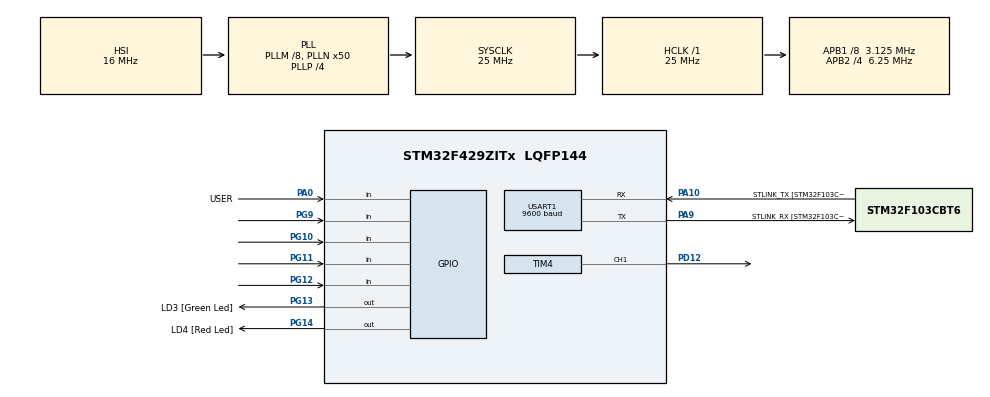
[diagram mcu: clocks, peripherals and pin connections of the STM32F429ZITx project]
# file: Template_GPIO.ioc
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Mcu.Family=STM32F4
Mcu.Name=STM32F429ZITx
Mcu.Package=LQFP144
NVIC.PriorityGroup=NVIC_PRIORITYGROUP_4
NVIC.USART1_IRQn=true\:0\:0\:false\:false\:true\:true\:true\:true
PA0/WKUP.GPIO_Label=USER
PA0/WKUP.Signal=GPIO_Input
PA10.GPIO_Label=STLINK_TX [STM32F103CBT6_PA2]
PA10.Mode=Asynchronous
PA10.Signal=USART1_RX
PA13.GPIO_Label=SWDIO
PA13.Mode=Serial_Wire
PA13.Signal=SYS_JTMS-SWDIO
PA14.GPIO_Label=SWCLK
PA14.Mode=Serial_Wire
PA14.Signal=SYS_JTCK-SWCLK
PA9.GPIO_Label=STLINK_RX [STM32F103CBT6_PA3]
PA9.Mode=Asynchronous
PA9.Signal=USART1_TX
PD12.Signal=S_TIM4_CH1
PG10.Signal=GPIO_Input
PG11.Signal=GPIO_Input
PG12.Signal=GPIO_Input
PG13.GPIO_Label=LD3 [Green Led]
PG13.Signal=GPIO_Output
PG14.GPIO_Label=LD4 [Red Led]
PG14.GPIO_Mode=GPIO_MODE_OUTPUT_PP
PG14.GPIO_PuPd=GPIO_NOPULL
PG14.GPIO_Speed=GPIO_SPEED_FREQ_LOW
PG14.Signal=GPIO_Output
PG9.Signal=GPIO_Input
PH0/OSC_IN.GPIO_Label=PH0-OSC_IN
PH0/OSC_IN.Mode=HSE-External-Oscillator
PH0/OSC_IN.Signal=RCC_OSC_IN
PH1/OSC_OUT.GPIO_Label=PH1-OSC_OUT
PH1/OSC_OUT.Mode=HSE-External-Oscillator
PH1/OSC_OUT.Signal=RCC_OSC_OUT
ProjectManager.HeapSize=0x200
ProjectManager.StackSize=0x400
ProjectManager.TargetToolchain=MDK-ARM V5.32
RCC.48MHZClocksFreq_Value=14285714.285714285
RCC.AHBFreq_Value=25000000
RCC.APB1CLKDivider=RCC_HCLK_DIV8
RCC.APB1Freq_Value=3125000
RCC.APB1TimFreq_Value=6250000
RCC.APB2CLKDivider=RCC_HCLK_DIV4
RCC.APB2Freq_Value=6250000
RCC.APB2TimFreq_Value=12500000
RCC.CortexFreq_Value=25000000
RCC.HCLKFreq_Value=25000000
RCC.HSE_VALUE=8000000
RCC.HSI_VALUE=16000000
RCC.LSE_VALUE=32768
RCC.PLLM=8
RCC.PLLN=50
RCC.PLLP=RCC_PLLP_DIV4
RCC.PLLQ=7
RCC.SYSCLKFreq_VALUE=25000000
RCC.SYSCLKSource=RCC_SYSCLKSOURCE_PLLCLK
RCC.VCOOutputFreq_Value=100000000
SH.S_TIM4_CH1.0=TIM4_CH1,PWM Generation1 CH1
TIM4.Channel-PWM\ Generation1\ CH1=TIM_CHANNEL_1
TIM4.OCMode_PWM-PWM\ Generation1\ CH1=TIM_OCMODE_PWM2
TIM4.OCPolarity_1=TIM_OCPOLARITY_LOW
TIM4.Period=8399
USART1.BaudRate=9600
USART1.VirtualMode=VM_ASYNC
VP_TIM4_VS_ClockSourceINT.Mode=Internal
board=STM32F429I-DISC1

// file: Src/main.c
/* USER CODE BEGIN Header */
/**
  ******************************************************************************
  * @file           : main.c
  * @brief          : Proiect MC - Control Ventilator cu Joystick si PWM
  ******************************************************************************
  */
/* USER CODE END Header */

#include "main.h"
#include <stdio.h>

TIM_HandleTypeDef htim4;
UART_HandleTypeDef huart1;

/* USER CODE BEGIN PV */
float pwm_value = 0.0f;
// Variabile pentru a afisa mesajele o singura data la apasare
uint8_t lock_A = 0, lock_B = 0, lock_C = 0, lock_D = 0;
/* USER CODE END PV */

void SystemClock_Config(void);
static void MX_GPIO_Init(void);
static void MX_USART1_UART_Init(void);
static void MX_TIM4_Init(void);

/* USER CODE BEGIN 0 */
// Redirectionare printf catre UART
#ifdef __GNUC__
  #define PUTCHAR_PROTOTYPE int __io_putchar(int ch)
#else
  #define PUTCHAR_PROTOTYPE int fputc(int ch, FILE *f)
#endif

PUTCHAR_PROTOTYPE
{
  HAL_UART_Transmit(&huart1, (uint8_t *)&ch, 1, 0xFFFF);
  return ch;
}
/* USER CODE END 0 */

int main(void)
{
  /* MCU Configuration */
  HAL_Init();
  SystemClock_Config();

  /* Initialize all configured peripherals */
  MX_GPIO_Init();
  MX_USART1_UART_Init();
  MX_TIM4_Init();

  /* USER CODE BEGIN 2 */
  // Pornire PWM pe pinul PD12
  HAL_TIM_PWM_Start(&htim4, TIM_CHANNEL_1);

  HAL_Delay(500);
  printf("\n\r====================================\r\n");
  printf("   PROIECT MC - CONTROL VENTILATOR\r\n");
  printf("   Studenti: Baroiu Vladut-Andrei, Epure Alexandru-Valentin\r\n");
  printf("   Grupa: 3132A\r\n");
  printf("====================================\r\n\r\n");
  /* USER CODE END 2 */

  while (1)
  {
    /* 1. JOY A (PG6) -> OPRIT */
    if (HAL_GPIO_ReadPin(GPIOG, GPIO_PIN_6) == GPIO_PIN_RESET) {
      if (lock_A == 0) {
        pwm_value = 0.0f;
        __HAL_TIM_SET_COMPARE(&htim4, TIM_CHANNEL_1, 0);
        printf("Comanda: OPRIT (0%%)\r\n");
        lock_A = 1;
      }
    } else { lock_A = 0; }

    /* 2. JOY B (PG9) -> MAXIM */
    if (HAL_GPIO_ReadPin(GPIOG, GPIO_PIN_9) == GPIO_PIN_RESET) {
      if (lock_B == 0) {
        pwm_value = 1.0f;
        __HAL_TIM_SET_COMPARE(&htim4, TIM_CHANNEL_1, 8399);
        printf("Comanda: MAXIM (100%%)\r\n");
        lock_B = 1;
      }
    } else { lock_B = 0; }

    /* 3. JOY C (PG10) -> CRESTE VITEZA +10% */
    if (HAL_GPIO_ReadPin(GPIOG, GPIO_PIN_10) == GPIO_PIN_RESET) {
      if (lock_C == 0) {
        if(pwm_value < 1.0f) pwm_value += 0.1f;
        if(pwm_value > 1.0f) pwm_value = 1.0f;
        __HAL_TIM_SET_COMPARE(&htim4, TIM_CHANNEL_1, (uint32_t)(pwm_value * 8399));
        printf("Turatie: %d%%\r\n", (int)(pwm_value * 100 + 0.5f));
        lock_C = 1;
      }
    } else { lock_C = 0; }

    /* 4. JOY D (PG11) -> SCADE VITEZA -10% */
    if (HAL_GPIO_ReadPin(GPIOG, GPIO_PIN_11) == GPIO_PIN_RESET) {
      if (lock_D == 0) {
        if(pwm_value > 0.0f) pwm_value -= 0.1f;
        if(pwm_value < 0.0f) pwm_value = 0.0f;
        __HAL_TIM_SET_COMPARE(&htim4, TIM_CHANNEL_1, (uint32_t)(pwm_value * 8399));
        printf("Turatie: %d%%\r\n", (int)(pwm_value * 100 + 0.5f));
        lock_D = 1;
      }
    } else { lock_D = 0; }

    // Feedback vizual
    if (pwm_value > 0.01f) {
        HAL_GPIO_WritePin(GPIOG, GPIO_PIN_13, GPIO_PIN_SET);
        HAL_GPIO_WritePin(GPIOG, GPIO_PIN_14, GPIO_PIN_RESET);
    } else {
        HAL_GPIO_WritePin(GPIOG, GPIO_PIN_13, GPIO_PIN_RESET);
        HAL_GPIO_WritePin(GPIOG, GPIO_PIN_14, GPIO_PIN_SET);
    }

    HAL_Delay(20);
  }
}

void SystemClock_Config(void)
{
  RCC_OscInitTypeDef RCC_OscInitStruct = {0};
  RCC_ClkInitTypeDef RCC_ClkInitStruct = {0};

  __HAL_RCC_PWR_CLK_ENABLE();
  __HAL_PWR_VOLTAGESCALING_CONFIG(PWR_REGULATOR_VOLTAGE_SCALE3);

  RCC_OscInitStruct.OscillatorType = RCC_OSCILLATORTYPE_HSI;
  RCC_OscInitStruct.HSIState = RCC_HSI_ON;
  RCC_OscInitStruct.HSICalibrationValue = RCC_HSICALIBRATION_DEFAULT;
  RCC_OscInitStruct.PLL.PLLState = RCC_PLL_ON;
  RCC_OscInitStruct.PLL.PLLSource = RCC_PLLSOURCE_HSI;
  RCC_OscInitStruct.PLL.PLLM = 8;
  RCC_OscInitStruct.PLL.PLLN = 50;
  RCC_OscInitStruct.PLL.PLLP = RCC_PLLP_DIV4;
  RCC_OscInitStruct.PLL.PLLQ = 7;
  HAL_RCC_OscConfig(&RCC_OscInitStruct);

  RCC_ClkInitStruct.ClockType = RCC_CLOCKTYPE_HCLK|RCC_CLOCKTYPE_SYSCLK|RCC_CLOCKTYPE_PCLK1|RCC_CLOCKTYPE_PCLK2;
  RCC_ClkInitStruct.SYSCLKSource = RCC_SYSCLKSOURCE_PLLCLK;
  RCC_ClkInitStruct.AHBCLKDivider = RCC_SYSCLK_DIV1;
  RCC_ClkInitStruct.APB1CLKDivider = RCC_HCLK_DIV8;
  RCC_ClkInitStruct.APB2CLKDivider = RCC_HCLK_DIV4;
  HAL_RCC_ClockConfig(&RCC_ClkInitStruct, FLASH_LATENCY_0);
}

static void MX_TIM4_Init(void)
{
  TIM_ClockConfigTypeDef sClockSourceConfig = {0};
  TIM_MasterConfigTypeDef sMasterConfig = {0};
  TIM_OC_InitTypeDef sConfigOC = {0};

  htim4.Instance = TIM4;
  htim4.Init.Prescaler = 0;
  htim4.Init.CounterMode = TIM_COUNTERMODE_UP;
  htim4.Init.Period = 8399;
  htim4.Init.ClockDivision = TIM_CLOCKDIVISION_DIV1;
  htim4.Init.AutoReloadPreload = TIM_AUTORELOAD_PRELOAD_DISABLE;
  HAL_TIM_Base_Init(&htim4);
  sClockSourceConfig.ClockSource = TIM_CLOCKSOURCE_INTERNAL;
  HAL_TIM_ConfigClockSource(&htim4, &sClockSourceConfig);
  HAL_TIM_PWM_Init(&htim4);
  sMasterConfig.MasterOutputTrigger = TIM_TRGO_RESET;
  sMasterConfig.MasterSlaveMode = TIM_MASTERSLAVEMODE_DISABLE;
  HAL_TIMEx_MasterConfigSynchronization(&htim4, &sMasterConfig);
  sConfigOC.OCMode = TIM_OCMODE_PWM1; // Mod PWM standard
  sConfigOC.Pulse = 0;
  sConfigOC.OCPolarity = TIM_OCPOLARITY_HIGH; // Activ High
  sConfigOC.OCFastMode = TIM_OCFAST_DISABLE;
  HAL_TIM_PWM_ConfigChannel(&htim4, &sConfigOC, TIM_CHANNEL_1);
  HAL_TIM_MspPostInit(&htim4);
}

static void MX_USART1_UART_Init(void)
{
  huart1.Instance = USART1;
  huart1.Init.BaudRate = 9600;
  huart1.Init.WordLength = UART_WORDLENGTH_8B;
  huart1.Init.StopBits = UART_STOPBITS_1;
  huart1.Init.Parity = UART_PARITY_NONE;
  huart1.Init.Mode = UART_MODE_TX_RX;
  huart1.Init.HwFlowCtl = UART_HWCONTROL_NONE;
  huart1.Init.OverSampling = UART_OVERSAMPLING_16;
  HAL_UART_Init(&huart1);

}

static void MX_GPIO_Init(void)
{
  GPIO_InitTypeDef GPIO_InitStruct = {0};
  __HAL_RCC_GPIOH_CLK_ENABLE();
  __HAL_RCC_GPIOA_CLK_ENABLE();
  __HAL_RCC_GPIOD_CLK_ENABLE();
  __HAL_RCC_GPIOG_CLK_ENABLE();

  HAL_GPIO_WritePin(GPIOG, GPIO_PIN_13|GPIO_PIN_14, GPIO_PIN_RESET);

  GPIO_InitStruct.Pin = GPIO_PIN_9|GPIO_PIN_10|GPIO_PIN_11|GPIO_PIN_6;
  GPIO_InitStruct.Mode = GPIO_MODE_INPUT;
  GPIO_InitStruct.Pull = GPIO_NOPULL;
  HAL_GPIO_Init(GPIOG, &GPIO_InitStruct);

  GPIO_InitStruct.Pin = GPIO_PIN_13|GPIO_PIN_14;
  GPIO_InitStruct.Mode = GPIO_MODE_OUTPUT_PP;
  GPIO_InitStruct.Pull = GPIO_NOPULL;
  GPIO_InitStruct.Speed = GPIO_SPEED_FREQ_LOW;
  HAL_GPIO_Init(GPIOG, &GPIO_InitStruct);
}

void Error_Handler(void) { while(1); }
